# LKS32MC03x register map
Vendor: Linko Ltd.; Series: LKS32MC03x; File version: 1.0
CPU: CM0 r1p0, little endian, MPU, no FPU, 3 interrupt priority bits
Registers are 32-bit, read-write, reset 0x0 unless marked. A register's access mark holds for its fields unless they carry their own. Offsets are from the block's base; [hi:lo] are bit positions; {n}, {i} and the like mark numbered series.

## HALL — HALL registers
Base 0x40010300
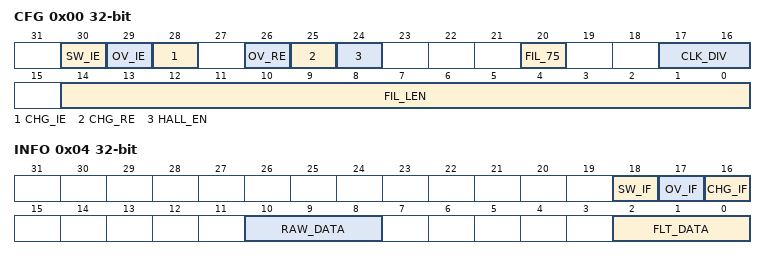
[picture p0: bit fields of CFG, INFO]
0x00 CFG — Hall Configuration Register
  [30] SW_IE — Software to trigger hall irq enable
    0=DISABLED (software trigger interrupt is disabled); 1=ENABLED (software trigger interrupt is enabled)
  [29] OV_IE — counter overflow interrupt enable
    0=DISABLED (counter overflow interrupt is disabled); 1=ENABLED (counter overflow interrupt is enabled)
  [28] CHG_IE — hall signal change interrupt enable
    0=DISABLED (hall signal change interrupt is disabled); 1=ENABLED (hall signal change interrupt is enabled)
  [26] OV_RE — counter overflow DMA request enable
    0=DISABLED (counter overflow DMA request is disabled); 1=ENABLED (counter overflow interrupt is enabled)
  [25] CHG_RE — hall signal change DMA request enable
    0=DISABLED (hall signal change DMA request is disabled); 1=ENABLED (hall signal change DMA request is enabled)
  [24] HALL_EN — hall enable
    0=DISABLED (hall module is disabled); 1=ENABLED (hall module is enabled)
  [20] FIL_75 — hall signal first filter:7_5 filter control bit
    0=DISABLED (hall signal 7_5 filter is disabled); 1=ENABLED (hall signal 7_5 filter is enabled)
  [17:16] CLK_DIV — hall clock frequency divider
    0=DIV1 (Divide 1); 1=DIV2 (Divide 2); 2=DIV4 (Divide 4); 3=DIV8 (Divide 8)
  [14:0] FIL_LEN — hall signal second filter:filter length control bits. Filter length from 1 to 32768
0x04 INFO — Hall Information register
  [18] SW_IF wo — software to trigger hall irq
  [17] OV_IF — overflow counter event
    0=NOV (read 0 means overflow counter event not happened, write 0 is useless); 1=OV (read 1 means overflow counter event happened, write 1 to clear)
  [16] CHG_IF — hall signal change event
    0=NCHG (read 0 means hall signal change event not happened, write 0 is useless); 1=CHG (read 1 means hall signal change event happened, write 1 to clear)
  [10:8] RAW_DATA ro — hall signal data without filtered
  [2:0] FLT_DATA ro — hall signal data with filtered
0x08 WIDTH ro — Hall Width Register
  [23:0] CAP_CNT — hall signal change event happened,captured hall counter value by hardware
0x0C TH — Hall Threshold Register
  [23:0] TH — overflow event target value
0x10 CNT — Hall Counter Register
  [23:0] CNT — hall counter value

## ADC — ADC registers
Base 0x40010400
0x00 DAT0 — ADC data0
  [15:0] DAT0 — ADC 0th sample data
0x04 DAT1 — ADC data1
  [15:0] DAT1 — ADC 1st sample data
0x08 DAT2 — ADC data2
  [15:0] DAT2 — ADC 2nd sample data
0x0C DAT3 — ADC data3
  [15:0] DAT3 — ADC 3rd sample data
{0x0+4i} DAT{i} (i=4..9) — ADC data{i}
  [15:0] DAT{i} — ADC {i}th sample data
0x30 LTH — low threshold
  [11:0] LTH — Data low threshold
0x34 HTH — high threshold
  [11:0] HTH — Data high threshold
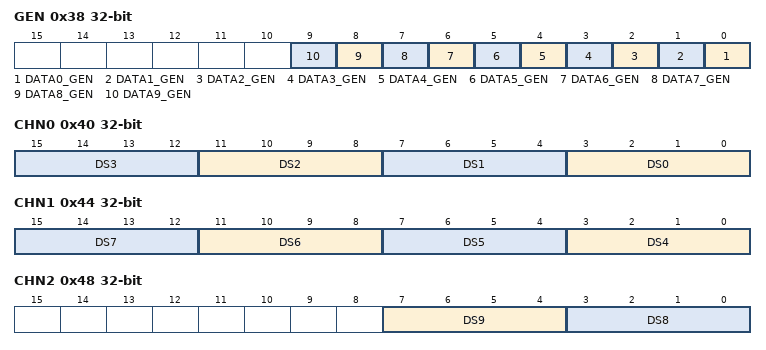
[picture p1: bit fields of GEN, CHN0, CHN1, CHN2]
0x38 GEN — Data monitor enable
  [n] DATA{n}_GEN (n=0..9) — Data{n} monitor enable
0x40 CHN0 — ADC data0/1/2/3 source
  [all] fields
    0=OPA0_OUT; {v}=ADC_CH{v} (v=1..10); 11=TEMP; 12=VSS
  [4n+3:4n] DS{n} (n=0..3) — Data{n} source
0x44 CHN1 — ADC data4/5/6/7 source
  [all] fields
    0=OPA0_OUT; {v}=ADC_CH{v} (v=1..10); 11=TEMP; 12=VSS
  [4n-13:4n-16] DS{n} (n=4..7) — Data{n} source
0x48 CHN2 — ADC data8/9 source
  [7:4] DS9 — Data9 source
    0=OPA0_OUT; {v}=ADC_CH{v} (v=1..10); 11=TEMP; 12=VSS
  [3:0] DS8 — Data8 source
    0=OPA0_OUT; {v}=ADC_CH{v} (v=1..10); 11=TEMP; 12=VSS
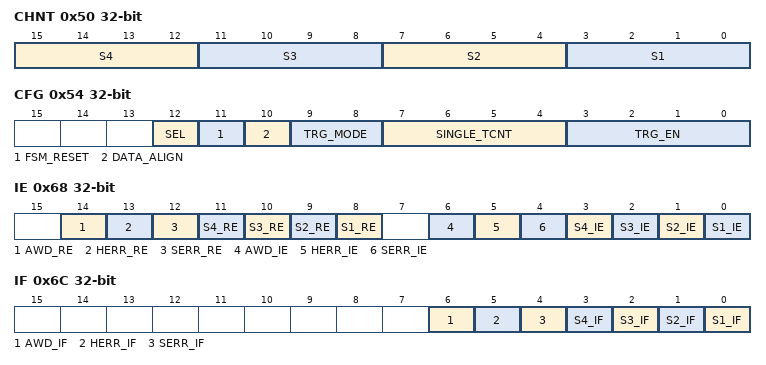
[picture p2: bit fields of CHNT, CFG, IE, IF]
0x50 CHNT — ADC channel numbers
  [15:12] S4 — 4th segment sample times
  [11:8] S3 — 3rd segment sample times
  [7:4] S2 — 2nd segment sample times
  [3:0] S1 — 1st segment sample times
0x54 CFG — ADC configuration
  [12] SEL — ADC Trigger source
    0=MCPWM (MCPWM trigger); 1=UTIMER (Utimer trigger)
  [11] FSM_RESET — sample state machine reset
  [10] DATA_ALIGN — ADC data alignment
    0=LEFT (left alignment, padding with 4'b0); 1=RIGHT (right alignment, sign bit extension at head)
  [9:8] TRG_MODE — trigger mode
    0=ONE_ROUND (One round sample); 1=TWO_ROUND (Two rounds sample); 3=FOUR_ROUND (Four rounds sample)
  [7:4] SINGLE_TCNT — single segment trigger counter
  [3:0] TRG_EN — trigger enable
0x58 SWT wo — ADC software trigger
  [15:0] SWT — write 0x5AA5 to trigger ADC sample
    0x5AA5=TRG (Trigger password)
0x60 DC — ADC DC offset of sample circuit A for low gain
  [7:0] OFFSET — DC offset value
0x64 AMC reset 0x200 — ADC amplification calibration of sample circuit A for low gain
  [9:0] AM — Amplification calibration value
0x68 IE — ADC interrupt enable
  [14] AWD_RE — ADC_DATx out of range DMA request enable
  [13] HERR_RE — Hardware trigger error interrupt enable
  [12] SERR_RE — Software trigger error interrupt enable
  [11] S4_RE — 4th segment sample finish interrupt enable
  [10] S3_RE — 3rd segment sample finish interrupt enable
  [9] S2_RE — 2nd segment sample finish interrupt enable
  [8] S1_RE — 1st segment sample finish interrupt enable
  [6] AWD_IE — ADC_DATx out of range interrrup enable
  [5] HERR_IE — Hardware trigger error interrupt enable
  [4] SERR_IE — Software trigger error interrupt enable
  [3] S4_IE — 4th segment sample finish interrupt enable
  [2] S3_IE — 3rd segment sample finish interrupt enable
  [1] S2_IE — 2nd segment sample finish interrupt enable
  [0] S1_IE — 1st segment sample finish interrupt enable
0x6C IF — ADC interrupt flag
  [6] AWD_IF — ADC_DATx is monitored and out of the threshold range
  [5] HERR_IF — Hardware trigger error interrupt, write 1 to clear
  [4] SERR_IF — Software trigger error interrupt, write 1 to clear
  [3] S4_IF — 4th segment sample finish interrupt, write 1 to clear
  [2] S3_IF — 3rd segment sample finish interrupt, write 1 to clear
  [1] S2_IF — 2nd segment sample finish interrupt, write 1 to clear
  [0] S1_IF — 1st segment sample finish interrupt, write 1 to clear

## Notices in the file
Copyright (C) 2012-2014 ARM Limited. All rights reserved.
Purpose: System Viewer Description (SVD) Example (Schema Version 1.1)
This is a description of a none-existent and incomplete device
for demonstration purposes only.
Redistribution and use in source and binary forms, with or without
modification, are permitted provided that the following conditions are met:
- Redistributions of source code must retain the above copyright
notice, this list of conditions and the following disclaimer.
- Redistributions in binary form must reproduce the above copyright
notice, this list of conditions and the following disclaimer in the
documentation and/or other materials provided with the distribution.
- Neither the name of ARM nor the names of its contributors may be used
to endorse or promote products derived from this software without
specific prior written permission.
THIS SOFTWARE IS PROVIDED BY THE COPYRIGHT HOLDERS AND CONTRIBUTORS "AS IS"
AND ANY EXPRESS OR IMPLIED WARRANTIES, INCLUDING, BUT NOT LIMITED TO, THE
IMPLIED WARRANTIES OF MERCHANTABILITY AND FITNESS FOR A PARTICULAR PURPOSE
ARE DISCLAIMED. IN NO EVENT SHALL COPYRIGHT HOLDERS AND CONTRIBUTORS BE
LIABLE FOR ANY DIRECT, INDIRECT, INCIDENTAL, SPECIAL, EXEMPLARY, OR
CONSEQUENTIAL DAMAGES (INCLUDING, BUT NOT LIMITED TO, PROCUREMENT OF
SUBSTITUTE GOODS OR SERVICES; LOSS OF USE, DATA, OR PROFITS; OR BUSINESS
INTERRUPTION) HOWEVER CAUSED AND ON ANY THEORY OF LIABILITY, WHETHER IN
CONTRACT, STRICT LIABILITY, OR TORT (INCLUDING NEGLIGENCE OR OTHERWISE)
ARISING IN ANY WAY OUT OF THE USE OF THIS SOFTWARE, EVEN IF ADVISED OF THE
POSSIBILITY OF SUCH DAMAGE.
